AUTOSAR XML (schema 00051)
package /adcm/AdaptiveApplicationSwComponentTypes
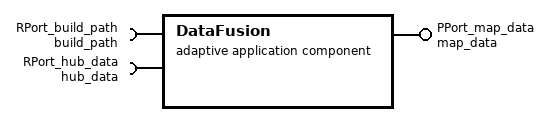
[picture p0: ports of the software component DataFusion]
  adaptive application sw component type DataFusion
    provide port PPort_map_data: provided-interface=map_data
    require port RPort_build_path: required-interface=build_path
    require port RPort_hub_data: required-interface=hub_data
package /adcm/Executables
  executable DataFusion: category=APPLICATION_LEVEL, minimum-timer-granularity=1000
    root sw component prototype DataFusion: application-type=DataFusion
